# DEFAULTS register map
File version: 1.0
Registers are 32-bit, read-write, reset 0xFF unless marked. A register's access mark holds for its fields unless they carry their own. Offsets are from the block's base; lines under a group give offsets from that group; [hi:lo] are bit positions; {n}, {i} and the like mark numbered series; 'fields as' and 'values as' point back to an identical list; <NAME> marks a mode.

## Memory map
0x40000000 DEV
0x40001000 INHERITING — The reset value comes from the peripheral, and a register states its own over it.

## DEV
Base 0x40000000
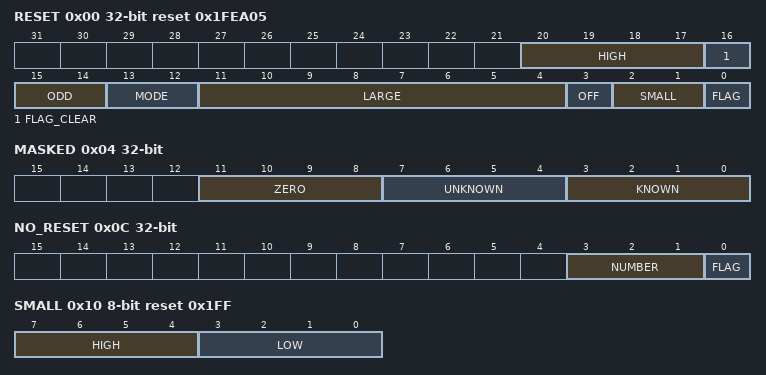
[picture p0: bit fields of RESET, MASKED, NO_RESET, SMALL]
0x00 RESET reset 0x1FEA05 — Reset value 0x1FEA05: a bool, small and large integers, enums, a write effect.
  [20:17] HIGH — Bits 17 to 20 hold 0xF.
  [16] FLAG_CLEAR write-1-clears — Bit 16 is 1, but a write effect has no default.
  [15:14] ODD — Bits 14 and 15 hold 3, and no variant has that value: no default, warned.
    0=A; 1=B
  [13:12] MODE — Bits 12 and 13 hold 2: a variant.
    0=A; 1=B; 2=C
  [11:4] LARGE — Bits 4 to 11 hold 0xA0.
  [3] OFF — Bit 3 is 0.
  [2:1] SMALL — Bits 1 and 2 hold 2.
  [0] FLAG — Bit 0 is 1.
0x04 MASKED (reset mask 0xF0F) — Reset value 0xFF, and a mask that knows bits 0 to 3 and 8 to 11 only.
  [11:8] ZERO — Bits 8 to 11 are known, and 0.
  [7:4] UNKNOWN — Bits 4 to 7 are out of the mask: no default.
  [3:0] KNOWN
0x08 PARTLY (reset mask 0xF) — A field with some of its bits out of the mask has no default.
  [5:2] MIDDLE
0x0C NO_RESET reset not defined — No resetValue at any level: its fields have no default.
  [3:1] NUMBER, [0] FLAG
0x10 SMALL 8-bit reset 0x1FF — An 8-bit register: the reset value is cut to its size.
  [7:4] HIGH, [3:0] LOW

## INHERITING — The reset value comes from the peripheral, and a register states its own over it.
Base 0x40001000
0x00 R reset 0x5
  [2:0] A
0x04 OWN reset 0x2
  [2:0] A
